# nrf51 register map
Vendor: Nordic Semiconductor; Series: nrf51; File version: 522
CPU: CM0 r3p1, little endian, no MPU, no FPU, 2 interrupt priority bits
Registers are 32-bit, read-write, reset 0x0 unless marked. A register's access mark holds for its fields unless they carry their own. Offsets are from the block's base; [hi:lo] are bit positions; lines under a group give offsets from that group; {n}, {i} and the like mark numbered series.

## NVMC — Non Volatile Memory Controller.
Base 0x4001E000
0x400 READY ro — Ready flag.
  [0] READY — NVMC ready.
    0=Busy (NVMC is busy (on-going write or erase operation).); 1=Ready (NVMC is ready.)
0x504 CONFIG — Configuration register.
  [1:0] WEN — Program write enable.
    0=Ren (Read only access.); 1=Wen (Write enabled.); 2=Een (Erase enabled.)
0x508 ERASEPAGE — Register for erasing a non-protected non-volatile memory page.
0x508 ERASEPCR1 (alternate view of ERASEPAGE) — Register for erasing a non-protected non-volatile memory page.
0x50C ERASEALL — Register for erasing all non-volatile user memory.
  [0] ERASEALL — Starts the erasing of all user NVM (code region 0/1 and UICR registers).
    0=NoOperation; 1=Erase (Start chip erase.)
0x510 ERASEPCR0 — Register for erasing a protected non-volatile memory page.
0x514 ERASEUICR — Register for start erasing User Information Congfiguration Registers.
  [0] ERASEUICR — It can only be used when all contents of code region 1 are erased.
    0=NoOperation; 1=Erase (Start UICR erase.)

## PPI — PPI controller.
Base 0x4001F000
{0x0+8i} TASKS_CHG[{i}] (i=0..3) group — Channel group tasks.
  0x00 EN wo — Enable channel group.
  0x04 DIS wo — Disable channel group.
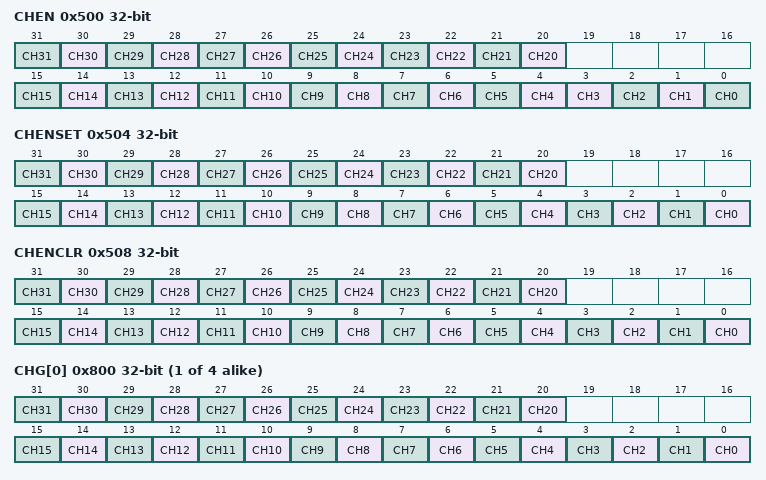
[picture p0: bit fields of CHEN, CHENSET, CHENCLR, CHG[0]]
0x500 CHEN — Channel enable.
  [n] CH{n} (n=20..31) — Enable PPI channel {n}.
    0=Disabled (Channel disabled.); 1=Enabled (Channel enabled.)
  [n] CH{n} (n=4..15) — Enable PPI channel {n}.
    0=Disabled (Channel disabled.); 1=Enabled (Channel enabled.)
  [3] CH3 — Enable PPI channel 3.
    0=Disabled (Channel disabled); 1=Enabled (Channel enabled)
  [2] CH2 — Enable PPI channel 2.
    0=Disabled (Channel disabled.); 1=Enabled (Channel enabled.)
  [1] CH1 — Enable PPI channel 1.
    0=Disabled (Channel disabled.); 1=Enabled (Channel enabled.)
  [0] CH0 — Enable PPI channel 0.
    0=Disabled (Channel disabled.); 1=Enabled (Channel enabled.)
0x504 CHENSET — Channel enable set.
  [all] fields
    on read: 0=Disabled (Channel disabled.); 1=Enabled (Channel enabled.) | on write: 1=Set (Enable channel on write.)
  [n] CH{n} (n=20..31) — Enable PPI channel {n}.
  [n] CH{n} (n=0..15) — Enable PPI channel {n}.
0x508 CHENCLR — Channel enable clear.
  [all] fields
    on read: 0=Disabled (Channel disabled.); 1=Enabled (Channel enabled.) | on write: 1=Clear (Disable channel on write.)
  [n] CH{n} (n=20..31) — Disable PPI channel {n}.
  [n] CH{n} (n=0..15) — Disable PPI channel {n}.
{0x510+8i} CH[{i}] (i=0..15) group — PPI Channel.
  0x00 EEP — Channel event end-point.
  0x04 TEP — Channel task end-point.
{0x800+4i} CHG[{i}] (i=0..3) — Channel group configuration.
  [all] fields
    0=Excluded (Channel excluded.); 1=Included (Channel included.)
  [n] CH{n} (n=20..31) — Include CH{n} in channel group.
  [n] CH{n} (n=0..15) — Include CH{n} in channel group.

## FICR — Factory Information Configuration.
Base 0x10000000
0x10 CODEPAGESIZE ro reset 0xFFFFFFFF — Code memory page size in bytes.
0x14 CODESIZE ro reset 0xFFFFFFFF — Code memory size in pages.
0x28 CLENR0 ro reset 0xFFFFFFFF — Length of code region 0 in bytes.
0x2C PPFC ro reset 0xFFFFFFFF — Pre-programmed factory code present.
  [7:0] PPFC
    255=NotPresent; 0=Present
0x34 NUMRAMBLOCK ro reset 0xFFFFFFFF — Number of individually controllable RAM blocks.
0x38 SIZERAMBLOCKS ro reset 0xFFFFFFFF — Size of RAM blocks in bytes.
{0x38+4i} SIZERAMBLOCK[{i}] (i=0..3) ro reset 0xFFFFFFFF (alternate view of SIZERAMBLOCKS) — Deprecated array of size of RAM block in bytes. This name is kept for backward compatinility purposes. Use SIZERAMBLOCKS instead.
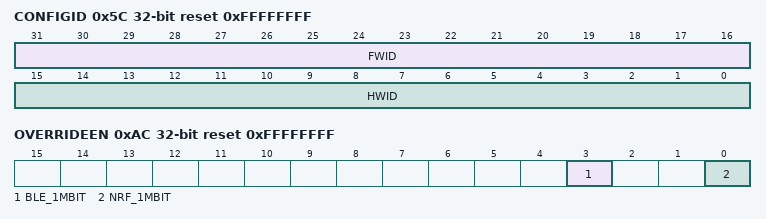
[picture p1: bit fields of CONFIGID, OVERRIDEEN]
0x5C CONFIGID ro reset 0xFFFFFFFF — Configuration identifier.
  [31:16] FWID — Firmware Identification Number pre-loaded into the flash.
  [15:0] HWID — Hardware Identification Number.
{0x60+4i} DEVICEID[{i}] (i=0..1) ro reset 0xFFFFFFFF — Device identifier.
{0x80+4i} ER[{i}] (i=0..3) ro reset 0xFFFFFFFF — Encryption root.
{0x90+4i} IR[{i}] (i=0..3) ro reset 0xFFFFFFFF — Identity root.
0xA0 DEVICEADDRTYPE ro reset 0xFFFFFFFF — Device address type.
  [0] DEVICEADDRTYPE
    0=Public address; 1=Random address
{0xA4+4i} DEVICEADDR[{i}] (i=0..1) ro reset 0xFFFFFFFF — Device address.
0xAC OVERRIDEEN ro reset 0xFFFFFFFF — Radio calibration override enable.
  [3] BLE_1MBIT — Override default values for BLE_1Mbit mode.
    0=Override the default values for BLE_1Mbit mode; 1=NotOverride (Do not override the default values for BLE_1Mbit mode.)
  [0] NRF_1MBIT — Override default values for NRF_1Mbit mode.
    0=Override the default values for NRF_1Mbit mode; 1=NotOverride (Do not override the default values for NRF_1Mbit mode.)
{0xB0+4i} NRF_1MBIT[{i}] (i=0..4) ro reset 0xFFFFFFFF — Override values for the overridden registers in RADIO for NRF_1Mbit mode.
{0xEC+4i} BLE_1MBIT[{i}] (i=0..4) ro reset 0xFFFFFFFF — Override values for the overridden registers in RADIO for BLE_1Mbit mode.

## UICR — User Information Configuration.
Base 0x10001000
0x00 CLENR0 reset 0xFFFFFFFF — Length of code region 0.
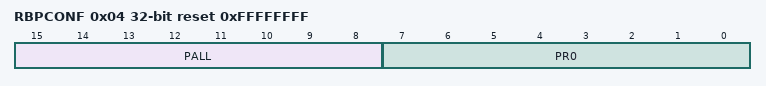
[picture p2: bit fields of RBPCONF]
0x04 RBPCONF reset 0xFFFFFFFF — Readback protection configuration.
  [15:8] PALL — Readback protect all code in the device.
    255=Disabled; 0=Enabled
  [7:0] PR0 — Readback protect region 0. Will be ignored if pre-programmed factory code is present on the chip.
    255=Disabled; 0=Enabled
0x08 XTALFREQ reset 0xFFFFFFFF — Reset value for CLOCK XTALFREQ register.
  [7:0] XTALFREQ
    255=16MHz Xtal is used; 0=32MHz Xtal is used
0x10 FWID ro reset 0xFFFFFFFF — Firmware ID.
  [15:0] FWID — Identification number for the firmware loaded into the chip.
0x14 BOOTLOADERADDR reset 0xFFFFFFFF — Bootloader start address.
{0x14+4i} NRFFW[{i}] (i=0..14) reset 0xFFFFFFFF (alternate view of BOOTLOADERADDR) — Reserved for Nordic firmware design.
{0x50+4i} NRFHW[{i}] (i=0..11) reset 0xFFFFFFFF — Reserved for Nordic hardware design.
{0x80+4i} CUSTOMER[{i}] (i=0..31) reset 0xFFFFFFFF — Reserved for customer.

## GPIO — General purpose input and output.
Base 0x50000000
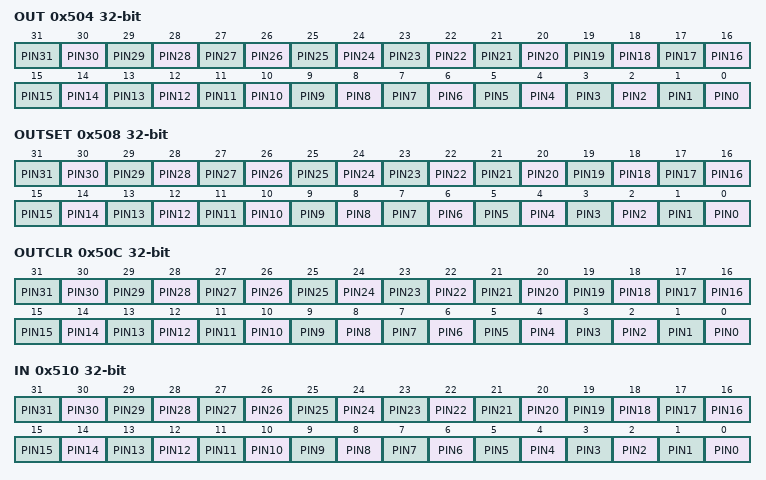
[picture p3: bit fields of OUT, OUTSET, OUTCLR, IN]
0x504 OUT — Write GPIO port.
  [all] fields
    0=Low (Pin driver is low.); 1=High (Pin driver is high.)
  [n] PIN{n} (n=0..31)
0x508 OUTSET — Set individual bits in GPIO port.
  [all] fields
    on read: 0=Low (Pin driver is low.); 1=High (Pin driver is high.) | on write: 1=Set (Set pin driver high.)
  [n] PIN{n} (n=0..31)
0x50C OUTCLR — Clear individual bits in GPIO port.
  [all] fields
    on read: 0=Low (Pin driver is low.); 1=High (Pin driver is high.) | on write: 1=Clear (Set pin driver low.)
  [n] PIN{n} (n=0..31)
0x510 IN ro — Read GPIO port.
  [all] fields
    0=Low (Pin input is low.); 1=High (Pin input is high.)
  [n] PIN{n} (n=0..31)
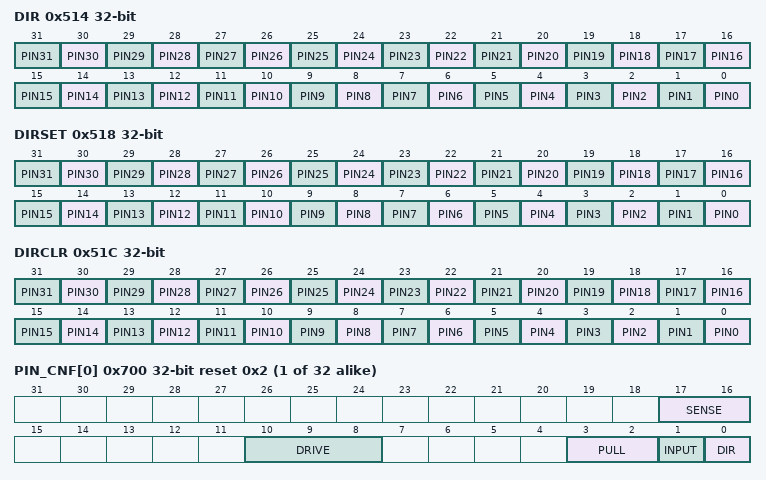
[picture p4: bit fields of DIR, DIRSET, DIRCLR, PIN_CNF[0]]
0x514 DIR — Direction of GPIO pins.
  [all] fields
    0=Input (Pin set as input.); 1=Output (Pin set as output.)
  [n] PIN{n} (n=0..31)
0x518 DIRSET
  [all] fields
    on read: 0=Input (Pin set as input.); 1=Output (Pin set as output.) | on write: 1=Set (Set pin as output.)
  [n] PIN{n} (n=0..31) — Set as output pin {n}.
0x51C DIRCLR — DIR clear register.
  [all] fields
    on read: 0=Input (Pin set as input.); 1=Output (Pin set as output.) | on write: 1=Clear (Set pin as input.)
  [n] PIN{n} (n=0..31) — Set as input pin {n}.
{0x700+4i} PIN_CNF[{i}] (i=0..31) reset 0x2 — Configuration of GPIO pins.
  [17:16] SENSE — Pin sensing mechanism.
    0=Disabled; 2=High (Wakeup on high level.); 3=Low (Wakeup on low level.)
  [10:8] DRIVE — Drive configuration.
    0=S0S1 (Standard '0', Standard '1'.); 1=H0S1 (High '0', Standard '1'.); 2=S0H1 (Standard '0', High '1'.); 3=H0H1 (High '0', High '1'.); 4=D0S1 (Disconnected '0', Standard '1'.); 5=D0H1 (Disconnected '0', High '1'.); 6=S0D1 (Standard '0', Disconnected '1'.); 7=H0D1 (High '0', Disconnected '1'.)
  [3:2] PULL — Pull-up or -down configuration.
    0=Disabled (No pull.); 1=Pulldown on pin; 3=Pullup on pin
  [1] INPUT — Connect or disconnect input path.
    0=Connect input pin; 1=Disconnect input pin
  [0] DIR — Pin direction.
    0=Input (Configure pin as an input pin.); 1=Output (Configure pin as an output pin.)
